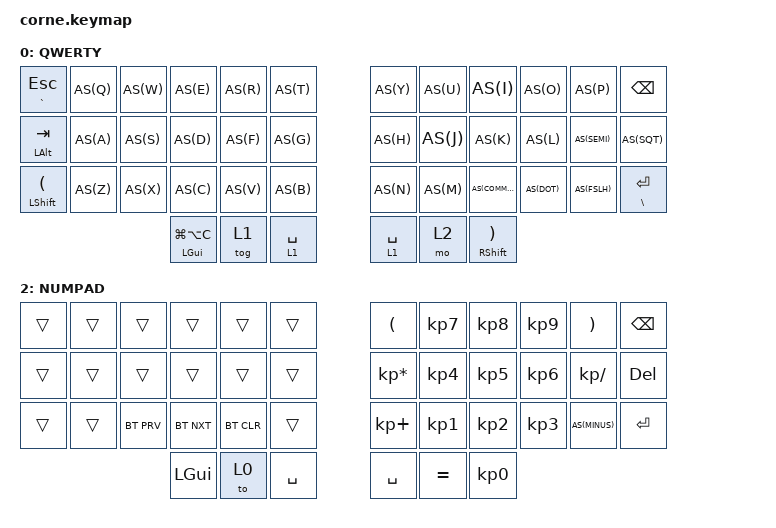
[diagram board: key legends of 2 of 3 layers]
/*
 * Copyright (c) 2020 The ZMK Contributors
 *
 * SPDX-License-Identifier: MIT
 */

#include <behaviors.dtsi>
#include <dt-bindings/zmk/keys.h>
#include <dt-bindings/zmk/bt.h>

#define AS(keycode) &as LS(keycode) keycode     // Autoshift Macro

&mt {
    flavor = "tap-preferred";
    tapping_term_ms = <200>;
};


/ {


    behaviors {
        as: auto_shift {
            compatible = "zmk,behavior-hold-tap";
            label = "AUTO_SHIFT";
            #binding-cells = <2>;
            tapping_term_ms = <275>;
            quick_tap_ms = <0>;
            flavor = "tap-preferred";
            bindings = <&kp>, <&kp>;
        };

	td: tapdance {
            compatible = "zmk,behavior-tap-dance";
            label = "TAPDANCE";
            #binding-cells = <0>;
            tapping-term-ms = <250>;
            bindings = <&kp LSHFT>, <&kp LS(LALT)>;
        };
    };


        keymap {
                compatible = "zmk,keymap";

                QWERTY {
                        bindings = <
   &mt GRAVE ESC AS(Q) AS(W) AS(E) AS(R) AS(T)       AS(Y) AS(U) AS(I) AS(O) AS(P) &kp BSPC
   &mt LALT TAB AS(A) AS(S) AS(D) AS(F) AS(G)        AS(H) AS(J) AS(K) AS(L) AS(SEMI) AS(SQT)
   &mt LSHFT LPAR AS(Z) AS(X) AS(C) AS(V) AS(B)      AS(N) AS(M) AS(COMMA) AS(DOT) AS(FSLH) &mt BSLH RET
                  &mt LGUI LG(LA(C)) &tog 1 &lt 1 SPACE        &lt 1 SPACE &mo 2 &mt RSHFT RPAR
                        >;
                };
                MEDIA_NAV {
                        bindings = <
   &caps_word AS(N1) AS(N2) AS(N3) AS(N4) AS(N5)                 AS(N6) AS(N7) AS(N8) AS(N9) AS(N0) &kp DEL
   &sk LCTRL &kp LG(LS(N4)) &kp C_PREV &kp C_PP &kp C_VOL_UP &kp C_NEXT  &kp LEFT &kp UP &kp DOWN &kp RIGHT &trans AS(MINUS)
   &td &kp LG(LS(LC(N4))) &trans &kp C_MUTE &kp C_VOL_DN &trans     &kp LC(A) &kp LC(E) &kp LG(LA(LEFT)) &kp LG(LA(RIGHT)) AS(LBKT) AS(RBKT)
                      &kp LGUI &tog 2 &to 0                &kp RET &to 2 &kp RALT
                        >;
                };
                NUMPAD {
                        bindings = <
   &trans &trans &trans &trans &trans &trans                   &kp LPAR &kp KP_N7 &kp KP_N8 &kp KP_N9 &kp RPAR &kp BSPC
   &trans &trans &trans &trans &trans &trans                 &kp KP_MULTIPLY &kp KP_N4 &kp KP_N5 &kp KP_N6 &kp KP_DIVIDE &kp DEL
   &trans &trans &bt BT_PRV &bt BT_NXT &bt BT_CLR &trans   &kp KP_PLUS &kp KP_N1 &kp KP_N2 &kp KP_N3 AS(MINUS) &kp RET
                      &kp LGUI &to 0 &kp SPACE      &kp SPACE &kp EQUAL &kp KP_N0
                        >;
                };
        };
};
